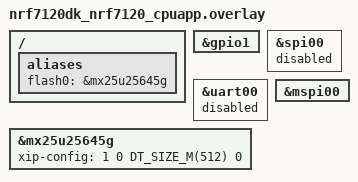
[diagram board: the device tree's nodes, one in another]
/*
 * Copyright (c) 2026 Nordic Semiconductor ASA
 *
 * SPDX-License-Identifier: Apache-2.0
 */

/ {
	aliases {
		flash0 = &mx25u25645g;
	};
};

&gpio1 {
	status = "okay";
};

&spi00 {
	status = "disabled";
};

&uart00 {
	status = "disabled";
};

&mspi00 {
	status = "okay";
};

&mx25u25645g {
	status = "okay";
	xip-config = <1 0 DT_SIZE_M(512) 0>;
};
